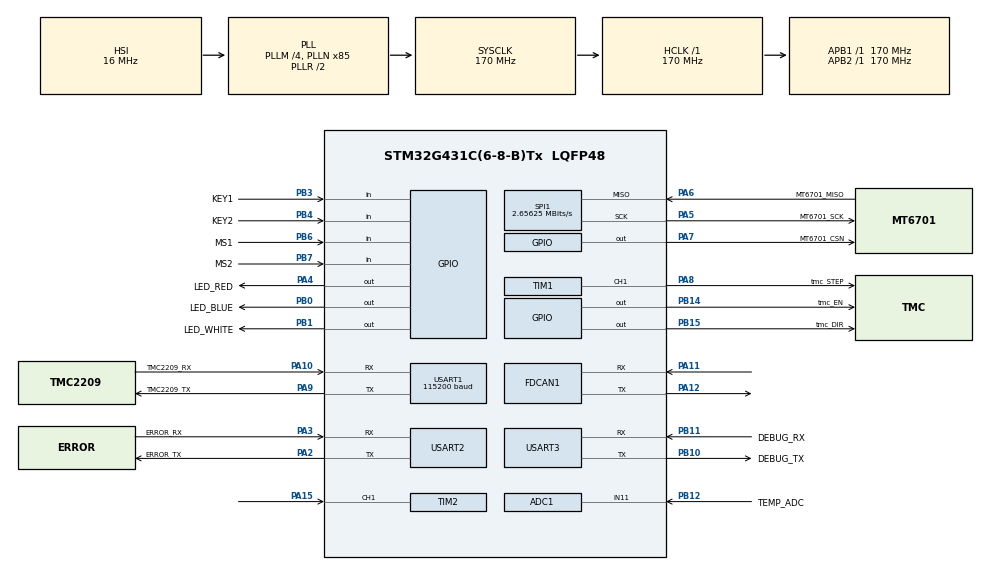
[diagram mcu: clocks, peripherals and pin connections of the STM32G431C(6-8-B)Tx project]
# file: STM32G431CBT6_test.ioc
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ADC1.Channel-1\#ChannelRegularConversion=ADC_CHANNEL_11
ADC1.NbrOfConversionFlag=1
ADC1.OffsetNumber-1\#ChannelRegularConversion=ADC_OFFSET_NONE
ADC1.Rank-1\#ChannelRegularConversion=1
ADC1.SamplingTime-1\#ChannelRegularConversion=ADC_SAMPLETIME_247CYCLES_5
ADC1.master=1
FDCAN1.AutoRetransmission=ENABLE
FDCAN1.CalculateBaudRateNominal=499999
FDCAN1.CalculateTimeBitNominal=2000
FDCAN1.CalculateTimeQuantumNominal=58.82352941176471
FDCAN1.ClockDivider=FDCAN_CLOCK_DIV1
FDCAN1.NominalPrescaler=10
FDCAN1.NominalTimeSeg1=28
FDCAN1.NominalTimeSeg2=5
FDCAN1.StdFiltersNbr=1
Mcu.Family=STM32G4
Mcu.Name=STM32G431C(6-8-B)Tx
Mcu.Package=LQFP48
NVIC.FDCAN1_IT0_IRQn=true\:4\:0\:true\:false\:true\:true\:true\:true
NVIC.PriorityGroup=NVIC_PRIORITYGROUP_4
NVIC.TIM1_UP_TIM16_IRQn=true\:0\:0\:false\:false\:true\:true\:true\:true
NVIC.TIM2_IRQn=true\:2\:0\:true\:false\:true\:true\:true\:true
NVIC.TIM6_DAC_IRQn=true\:1\:0\:true\:false\:true\:true\:true\:true
NVIC.USART2_IRQn=true\:3\:0\:true\:false\:true\:true\:true\:true
NVIC.USART3_IRQn=true\:5\:0\:true\:false\:true\:true\:true\:true
PA10.GPIO_Label=TMC2209_RX
PA10.Mode=Asynchronous
PA10.Signal=USART1_RX
PA11.Mode=FDCAN_Activate
PA11.Signal=FDCAN1_RX
PA12.Mode=FDCAN_Activate
PA12.Signal=FDCAN1_TX
PA13.Mode=Serial_Wire
PA13.Signal=SYS_JTMS-SWDIO
PA14.Mode=Serial_Wire
PA14.Signal=SYS_JTCK-SWCLK
PA15.Signal=S_TIM2_CH1
PA2.GPIO_Label=ERROR_TX
PA2.Mode=Asynchronous
PA2.Signal=USART2_TX
PA3.GPIO_Label=ERROR_RX
PA3.Mode=Asynchronous
PA3.Signal=USART2_RX
PA4.GPIO_Label=LED_RED
PA4.Signal=GPIO_Output
PA5.GPIO_Label=MT6701_SCK
PA5.Mode=RX_Only_Simplex_Unidirect_Master
PA5.Signal=SPI1_SCK
PA6.GPIO_Label=MT6701_MISO
PA6.Mode=RX_Only_Simplex_Unidirect_Master
PA6.Signal=SPI1_MISO
PA7.GPIO_Label=MT6701_CSN
PA7.Signal=GPIO_Output
PA8.GPIO_Label=tmc_STEP
PA8.Signal=S_TIM1_CH1
PA9.GPIO_Label=TMC2209_TX
PA9.Mode=Asynchronous
PA9.Signal=USART1_TX
PB0.GPIO_Label=LED_BLUE
PB0.Signal=GPIO_Output
PB1.GPIO_Label=LED_WHITE
PB1.Signal=GPIO_Output
PB10.GPIO_Label=DEBUG_TX
PB10.Mode=Asynchronous
PB10.Signal=USART3_TX
PB11.GPIO_Label=DEBUG_RX
PB11.Mode=Asynchronous
PB11.Signal=USART3_RX
PB12.GPIO_Label=TEMP_ADC
PB12.Mode=IN11-Single-Ended
PB12.Signal=ADC1_IN11
PB14.GPIO_Label=tmc_EN
PB14.GPIO_PuPd=GPIO_PULLUP
PB14.PinState=GPIO_PIN_SET
PB14.Signal=GPIO_Output
PB15.GPIO_Label=tmc_DIR
PB15.Signal=GPIO_Output
PB3.GPIO_Label=KEY1
PB3.GPIO_PuPd=GPIO_PULLUP
PB3.Signal=GPIO_Input
PB4.GPIO_Label=KEY2
PB4.GPIO_PuPd=GPIO_PULLUP
PB4.Signal=GPIO_Input
PB6.GPIO_Label=MS1
PB6.GPIO_PuPd=GPIO_PULLUP
PB6.Signal=GPIO_Input
PB7.GPIO_Label=MS2
PB7.GPIO_PuPd=GPIO_PULLUP
PB7.Signal=GPIO_Input
PF0-OSC_IN.Mode=HSE-External-Oscillator
PF0-OSC_IN.Signal=RCC_OSC_IN
PF1-OSC_OUT.Mode=HSE-External-Oscillator
PF1-OSC_OUT.Signal=RCC_OSC_OUT
ProjectManager.HeapSize=0x200
ProjectManager.StackSize=0x400
ProjectManager.TargetToolchain=MDK-ARM V5.32
RCC.ADC12Freq_Value=170000000
RCC.AHBFreq_Value=170000000
RCC.APB1Freq_Value=170000000
RCC.APB1TimFreq_Value=170000000
RCC.APB2Freq_Value=170000000
RCC.APB2TimFreq_Value=170000000
RCC.CortexFreq_Value=170000000
RCC.EXTERNAL_CLOCK_VALUE=12288000
RCC.HCLKFreq_Value=170000000
RCC.HSE_VALUE=8000000
RCC.HSI48_VALUE=48000000
RCC.HSI_VALUE=16000000
RCC.LSE_VALUE=32768
RCC.PLLM=RCC_PLLM_DIV4
RCC.PLLN=85
RCC.SYSCLKFreq_VALUE=170000000
RCC.SYSCLKSource=RCC_SYSCLKSOURCE_PLLCLK
RCC.USBFreq_Value=170000000
RCC.VCOOutputFreq_Value=340000000
SH.S_TIM1_CH1.0=TIM1_CH1,PWM Generation1 CH1
SH.S_TIM2_CH1.0=TIM2_CH1,PWM_Input_1
SPI1.BaudRatePrescaler=SPI_BAUDRATEPRESCALER_64
SPI1.CLKPolarity=SPI_POLARITY_HIGH
SPI1.CRCCalculation=SPI_CRCCALCULATION_DISABLE
SPI1.CalculateBaudRate=2.65625 MBits/s
SPI1.DataSize=SPI_DATASIZE_8BIT
SPI1.Direction=SPI_DIRECTION_2LINES_RXONLY
SPI1.Mode=SPI_MODE_MASTER
SPI1.NSSPMode=SPI_NSS_PULSE_DISABLE
SPI1.VirtualType=VM_MASTER
TIM1.AutomaticOutput=TIM_AUTOMATICOUTPUT_ENABLE
TIM1.Channel-PWM\ Generation1\ CH1=TIM_CHANNEL_1
TIM1.PeriodNoDither=1000
TIM1.Prescaler=169
TIM2.ICFilter_1=4
TIM2.ICFilter_2=4
TIM2.PeriodNoDither=4294967295
TIM2.Prescaler=169
TIM6.PeriodNoDither=999
TIM6.Prescaler=169
USART1.BaudRate=115200
USART1.VirtualMode-Asynchronous=VM_ASYNC
USART2.VirtualMode-Asynchronous=VM_ASYNC
USART3.VirtualMode-Asynchronous=VM_ASYNC
VP_SYS_VS_DBSignals.Mode=DisableDeadBatterySignals
VP_TIM1_VS_ClockSourceINT.Mode=Internal
VP_TIM2_VS_ClockSourceINT.Mode=Internal
VP_TIM6_VS_ClockSourceINT.Mode=Enable_Timer
board=custom

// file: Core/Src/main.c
/* USER CODE BEGIN Header */
/**
 ******************************************************************************
 * @file           : main.c
 * @brief          : Main program body
 ******************************************************************************
 * @attention
 *
 * Copyright (c) 2026 STMicroelectronics.
 * All rights reserved.
 *
 * This software is licensed under terms that can be found in the LICENSE file
 * in the root directory of this software component.
 * If no LICENSE file comes with this software, it is provided AS-IS.
 *
 ******************************************************************************
 */
/* USER CODE END Header */
#include "main.h"

/* USER CODE BEGIN Includes */
#include "../../Src/Step42App.h"
/* USER CODE END Includes */

ADC_HandleTypeDef hadc1;

FDCAN_HandleTypeDef hfdcan1;

SPI_HandleTypeDef hspi1;

TIM_HandleTypeDef htim1;
TIM_HandleTypeDef htim2;
TIM_HandleTypeDef htim6;

UART_HandleTypeDef huart1;
UART_HandleTypeDef huart2;
UART_HandleTypeDef huart3;

void SystemClock_Config(void);
static void MX_GPIO_Init(void);
static void MX_FDCAN1_Init(void);
static void MX_SPI1_Init(void);
static void MX_TIM1_Init(void);
static void MX_TIM2_Init(void);
static void MX_USART1_UART_Init(void);
static void MX_USART2_UART_Init(void);
static void MX_TIM6_Init(void);
static void MX_ADC1_Init(void);
static void MX_USART3_UART_Init(void);

int main(void)
{

  /* MCU Configuration--------------------------------------------------------*/

  /* Reset of all peripherals, Initializes the Flash interface and the Systick. */
  HAL_Init();

  /* Configure the system clock */
  SystemClock_Config();

  /* Initialize all configured peripherals */
  MX_GPIO_Init();
  MX_FDCAN1_Init();
  MX_SPI1_Init();
  MX_TIM1_Init();
  MX_TIM2_Init();
  MX_USART1_UART_Init();
  MX_USART2_UART_Init();
  MX_TIM6_Init();
  MX_ADC1_Init();
  MX_USART3_UART_Init();
  /* USER CODE BEGIN 2 */
  Step42App_Init();
  /* USER CODE END 2 */

  /* Infinite loop */
  while (1)
  {

    /* USER CODE BEGIN 3 */
    Step42App_Loop();
  }
  /* USER CODE END 3 */
}

void SystemClock_Config(void)
{
  RCC_OscInitTypeDef RCC_OscInitStruct = {0};
  RCC_ClkInitTypeDef RCC_ClkInitStruct = {0};

  /** Configure the main internal regulator output voltage
  */
  HAL_PWREx_ControlVoltageScaling(PWR_REGULATOR_VOLTAGE_SCALE1_BOOST);

  /** Initializes the RCC Oscillators according to the specified parameters
  * in the RCC_OscInitTypeDef structure.
  */
  RCC_OscInitStruct.OscillatorType = RCC_OSCILLATORTYPE_HSI;
  RCC_OscInitStruct.HSIState = RCC_HSI_ON;
  RCC_OscInitStruct.HSICalibrationValue = RCC_HSICALIBRATION_DEFAULT;
  RCC_OscInitStruct.PLL.PLLState = RCC_PLL_ON;
  RCC_OscInitStruct.PLL.PLLSource = RCC_PLLSOURCE_HSI;
  RCC_OscInitStruct.PLL.PLLM = RCC_PLLM_DIV4;
  RCC_OscInitStruct.PLL.PLLN = 85;
  RCC_OscInitStruct.PLL.PLLP = RCC_PLLP_DIV2;
  RCC_OscInitStruct.PLL.PLLQ = RCC_PLLQ_DIV2;
  RCC_OscInitStruct.PLL.PLLR = RCC_PLLR_DIV2;
  if (HAL_RCC_OscConfig(&RCC_OscInitStruct) != HAL_OK)
  {
    Error_Handler();
  }

  /** Initializes the CPU, AHB and APB buses clocks
  */
  RCC_ClkInitStruct.ClockType = RCC_CLOCKTYPE_HCLK|RCC_CLOCKTYPE_SYSCLK
                              |RCC_CLOCKTYPE_PCLK1|RCC_CLOCKTYPE_PCLK2;
  RCC_ClkInitStruct.SYSCLKSource = RCC_SYSCLKSOURCE_PLLCLK;
  RCC_ClkInitStruct.AHBCLKDivider = RCC_SYSCLK_DIV1;
  RCC_ClkInitStruct.APB1CLKDivider = RCC_HCLK_DIV1;
  RCC_ClkInitStruct.APB2CLKDivider = RCC_HCLK_DIV1;

  if (HAL_RCC_ClockConfig(&RCC_ClkInitStruct, FLASH_LATENCY_4) != HAL_OK)
  {
    Error_Handler();
  }
}

static void MX_ADC1_Init(void)
{

  ADC_MultiModeTypeDef multimode = {0};
  ADC_ChannelConfTypeDef sConfig = {0};

  /** Common config
  */
  hadc1.Instance = ADC1;
  hadc1.Init.ClockPrescaler = ADC_CLOCK_SYNC_PCLK_DIV4;
  hadc1.Init.Resolution = ADC_RESOLUTION_12B;
  hadc1.Init.DataAlign = ADC_DATAALIGN_RIGHT;
  hadc1.Init.GainCompensation = 0;
  hadc1.Init.ScanConvMode = ADC_SCAN_DISABLE;
  hadc1.Init.EOCSelection = ADC_EOC_SINGLE_CONV;
  hadc1.Init.LowPowerAutoWait = DISABLE;
  hadc1.Init.ContinuousConvMode = DISABLE;
  hadc1.Init.NbrOfConversion = 1;
  hadc1.Init.DiscontinuousConvMode = DISABLE;
  hadc1.Init.ExternalTrigConv = ADC_SOFTWARE_START;
  hadc1.Init.ExternalTrigConvEdge = ADC_EXTERNALTRIGCONVEDGE_NONE;
  hadc1.Init.DMAContinuousRequests = DISABLE;
  hadc1.Init.Overrun = ADC_OVR_DATA_PRESERVED;
  hadc1.Init.OversamplingMode = DISABLE;
  if (HAL_ADC_Init(&hadc1) != HAL_OK)
  {
    Error_Handler();
  }

  /** Configure the ADC multi-mode
  */
  multimode.Mode = ADC_MODE_INDEPENDENT;
  if (HAL_ADCEx_MultiModeConfigChannel(&hadc1, &multimode) != HAL_OK)
  {
    Error_Handler();
  }

  /** Configure Regular Channel
  */
  sConfig.Channel = ADC_CHANNEL_11;
  sConfig.Rank = ADC_REGULAR_RANK_1;
  sConfig.SamplingTime = ADC_SAMPLETIME_247CYCLES_5;
  sConfig.SingleDiff = ADC_SINGLE_ENDED;
  sConfig.OffsetNumber = ADC_OFFSET_NONE;
  sConfig.Offset = 0;
  if (HAL_ADC_ConfigChannel(&hadc1, &sConfig) != HAL_OK)
  {
    Error_Handler();
  }

}

static void MX_FDCAN1_Init(void)
{

  hfdcan1.Instance = FDCAN1;
  hfdcan1.Init.ClockDivider = FDCAN_CLOCK_DIV1;
  hfdcan1.Init.FrameFormat = FDCAN_FRAME_CLASSIC;
  hfdcan1.Init.Mode = FDCAN_MODE_NORMAL;
  hfdcan1.Init.AutoRetransmission = ENABLE;
  hfdcan1.Init.TransmitPause = DISABLE;
  hfdcan1.Init.ProtocolException = DISABLE;
  hfdcan1.Init.NominalPrescaler = 10;
  hfdcan1.Init.NominalSyncJumpWidth = 1;
  hfdcan1.Init.NominalTimeSeg1 = 28;
  hfdcan1.Init.NominalTimeSeg2 = 5;
  hfdcan1.Init.DataPrescaler = 1;
  hfdcan1.Init.DataSyncJumpWidth = 1;
  hfdcan1.Init.DataTimeSeg1 = 1;
  hfdcan1.Init.DataTimeSeg2 = 1;
  hfdcan1.Init.StdFiltersNbr = 1;
  hfdcan1.Init.ExtFiltersNbr = 0;
  hfdcan1.Init.TxFifoQueueMode = FDCAN_TX_FIFO_OPERATION;
  if (HAL_FDCAN_Init(&hfdcan1) != HAL_OK)
  {
    Error_Handler();
  }

}

static void MX_SPI1_Init(void)
{

  /* SPI1 parameter configuration*/
  hspi1.Instance = SPI1;
  hspi1.Init.Mode = SPI_MODE_MASTER;
  hspi1.Init.Direction = SPI_DIRECTION_2LINES_RXONLY;
  hspi1.Init.DataSize = SPI_DATASIZE_8BIT;
  hspi1.Init.CLKPolarity = SPI_POLARITY_HIGH;
  hspi1.Init.CLKPhase = SPI_PHASE_1EDGE;
  hspi1.Init.NSS = SPI_NSS_SOFT;
  hspi1.Init.BaudRatePrescaler = SPI_BAUDRATEPRESCALER_64;
  hspi1.Init.FirstBit = SPI_FIRSTBIT_MSB;
  hspi1.Init.TIMode = SPI_TIMODE_DISABLE;
  hspi1.Init.CRCCalculation = SPI_CRCCALCULATION_DISABLE;
  hspi1.Init.CRCPolynomial = 7;
  hspi1.Init.CRCLength = SPI_CRC_LENGTH_DATASIZE;
  hspi1.Init.NSSPMode = SPI_NSS_PULSE_DISABLE;
  if (HAL_SPI_Init(&hspi1) != HAL_OK)
  {
    Error_Handler();
  }

}

static void MX_TIM1_Init(void)
{

  TIM_ClockConfigTypeDef sClockSourceConfig = {0};
  TIM_MasterConfigTypeDef sMasterConfig = {0};
  TIM_OC_InitTypeDef sConfigOC = {0};
  TIM_BreakDeadTimeConfigTypeDef sBreakDeadTimeConfig = {0};

  htim1.Instance = TIM1;
  htim1.Init.Prescaler = 169;
  htim1.Init.CounterMode = TIM_COUNTERMODE_UP;
  htim1.Init.Period = 1000;
  htim1.Init.ClockDivision = TIM_CLOCKDIVISION_DIV1;
  htim1.Init.RepetitionCounter = 0;
  htim1.Init.AutoReloadPreload = TIM_AUTORELOAD_PRELOAD_DISABLE;
  if (HAL_TIM_Base_Init(&htim1) != HAL_OK)
  {
    Error_Handler();
  }
  sClockSourceConfig.ClockSource = TIM_CLOCKSOURCE_INTERNAL;
  if (HAL_TIM_ConfigClockSource(&htim1, &sClockSourceConfig) != HAL_OK)
  {
    Error_Handler();
  }
  if (HAL_TIM_PWM_Init(&htim1) != HAL_OK)
  {
    Error_Handler();
  }
  sMasterConfig.MasterOutputTrigger = TIM_TRGO_RESET;
  sMasterConfig.MasterOutputTrigger2 = TIM_TRGO2_RESET;
  sMasterConfig.MasterSlaveMode = TIM_MASTERSLAVEMODE_DISABLE;
  if (HAL_TIMEx_MasterConfigSynchronization(&htim1, &sMasterConfig) != HAL_OK)
  {
    Error_Handler();
  }
  sConfigOC.OCMode = TIM_OCMODE_PWM1;
  sConfigOC.Pulse = 0;
  sConfigOC.OCPolarity = TIM_OCPOLARITY_HIGH;
  sConfigOC.OCNPolarity = TIM_OCNPOLARITY_HIGH;
  sConfigOC.OCFastMode = TIM_OCFAST_DISABLE;
  sConfigOC.OCIdleState = TIM_OCIDLESTATE_RESET;
  sConfigOC.OCNIdleState = TIM_OCNIDLESTATE_RESET;
  if (HAL_TIM_PWM_ConfigChannel(&htim1, &sConfigOC, TIM_CHANNEL_1) != HAL_OK)
  {
    Error_Handler();
  }
  sBreakDeadTimeConfig.OffStateRunMode = TIM_OSSR_DISABLE;
  sBreakDeadTimeConfig.OffStateIDLEMode = TIM_OSSI_DISABLE;
  sBreakDeadTimeConfig.LockLevel = TIM_LOCKLEVEL_OFF;
  sBreakDeadTimeConfig.DeadTime = 0;
  sBreakDeadTimeConfig.BreakState = TIM_BREAK_DISABLE;
  sBreakDeadTimeConfig.BreakPolarity = TIM_BREAKPOLARITY_HIGH;
  sBreakDeadTimeConfig.BreakFilter = 0;
  sBreakDeadTimeConfig.BreakAFMode = TIM_BREAK_AFMODE_INPUT;
  sBreakDeadTimeConfig.Break2State = TIM_BREAK2_DISABLE;
  sBreakDeadTimeConfig.Break2Polarity = TIM_BREAK2POLARITY_HIGH;
  sBreakDeadTimeConfig.Break2Filter = 0;
  sBreakDeadTimeConfig.Break2AFMode = TIM_BREAK_AFMODE_INPUT;
  sBreakDeadTimeConfig.AutomaticOutput = TIM_AUTOMATICOUTPUT_ENABLE;
  if (HAL_TIMEx_ConfigBreakDeadTime(&htim1, &sBreakDeadTimeConfig) != HAL_OK)
  {
    Error_Handler();
  }
  HAL_TIM_MspPostInit(&htim1);

}

static void MX_TIM2_Init(void)
{

  TIM_ClockConfigTypeDef sClockSourceConfig = {0};
  TIM_SlaveConfigTypeDef sSlaveConfig = {0};
  TIM_IC_InitTypeDef sConfigIC = {0};
  TIM_MasterConfigTypeDef sMasterConfig = {0};

  htim2.Instance = TIM2;
  htim2.Init.Prescaler = 169;
  htim2.Init.CounterMode = TIM_COUNTERMODE_UP;
  htim2.Init.Period = 4294967295;
  htim2.Init.ClockDivision = TIM_CLOCKDIVISION_DIV1;
  htim2.Init.AutoReloadPreload = TIM_AUTORELOAD_PRELOAD_DISABLE;
  if (HAL_TIM_Base_Init(&htim2) != HAL_OK)
  {
    Error_Handler();
  }
  sClockSourceConfig.ClockSource = TIM_CLOCKSOURCE_INTERNAL;
  if (HAL_TIM_ConfigClockSource(&htim2, &sClockSourceConfig) != HAL_OK)
  {
    Error_Handler();
  }
  if (HAL_TIM_IC_Init(&htim2) != HAL_OK)
  {
    Error_Handler();
  }
  sSlaveConfig.SlaveMode = TIM_SLAVEMODE_RESET;
  sSlaveConfig.InputTrigger = TIM_TS_TI1FP1;
  sSlaveConfig.TriggerPolarity = TIM_INPUTCHANNELPOLARITY_RISING;
  sSlaveConfig.TriggerPrescaler = TIM_ICPSC_DIV1;
  sSlaveConfig.TriggerFilter = 4;
  if (HAL_TIM_SlaveConfigSynchro(&htim2, &sSlaveConfig) != HAL_OK)
  {
    Error_Handler();
  }
  sConfigIC.ICPolarity = TIM_INPUTCHANNELPOLARITY_RISING;
  sConfigIC.ICSelection = TIM_ICSELECTION_DIRECTTI;
  sConfigIC.ICPrescaler = TIM_ICPSC_DIV1;
  sConfigIC.ICFilter = 4;
  if (HAL_TIM_IC_ConfigChannel(&htim2, &sConfigIC, TIM_CHANNEL_1) != HAL_OK)
  {
    Error_Handler();
  }
  sConfigIC.ICPolarity = TIM_INPUTCHANNELPOLARITY_FALLING;
  sConfigIC.ICSelection = TIM_ICSELECTION_INDIRECTTI;
  if (HAL_TIM_IC_ConfigChannel(&htim2, &sConfigIC, TIM_CHANNEL_2) != HAL_OK)
  {
    Error_Handler();
  }
  sMasterConfig.MasterOutputTrigger = TIM_TRGO_RESET;
  sMasterConfig.MasterSlaveMode = TIM_MASTERSLAVEMODE_DISABLE;
  if (HAL_TIMEx_MasterConfigSynchronization(&htim2, &sMasterConfig) != HAL_OK)
  {
    Error_Handler();
  }

}

static void MX_TIM6_Init(void)
{

  TIM_MasterConfigTypeDef sMasterConfig = {0};

  htim6.Instance = TIM6;
  htim6.Init.Prescaler = 169;
  htim6.Init.CounterMode = TIM_COUNTERMODE_UP;
  htim6.Init.Period = 999;
  htim6.Init.AutoReloadPreload = TIM_AUTORELOAD_PRELOAD_DISABLE;
  if (HAL_TIM_Base_Init(&htim6) != HAL_OK)
  {
    Error_Handler();
  }
  sMasterConfig.MasterOutputTrigger = TIM_TRGO_RESET;
  sMasterConfig.MasterSlaveMode = TIM_MASTERSLAVEMODE_DISABLE;
  if (HAL_TIMEx_MasterConfigSynchronization(&htim6, &sMasterConfig) != HAL_OK)
  {
    Error_Handler();
  }

}

static void MX_USART1_UART_Init(void)
{

  huart1.Instance = USART1;
  huart1.Init.BaudRate = 115200;
  huart1.Init.WordLength = UART_WORDLENGTH_8B;
  huart1.Init.StopBits = UART_STOPBITS_1;
  huart1.Init.Parity = UART_PARITY_NONE;
  huart1.Init.Mode = UART_MODE_TX_RX;
  huart1.Init.HwFlowCtl = UART_HWCONTROL_NONE;
  huart1.Init.OverSampling = UART_OVERSAMPLING_16;
  huart1.Init.OneBitSampling = UART_ONE_BIT_SAMPLE_DISABLE;
  huart1.Init.ClockPrescaler = UART_PRESCALER_DIV1;
  huart1.AdvancedInit.AdvFeatureInit = UART_ADVFEATURE_NO_INIT;
  if (HAL_UART_Init(&huart1) != HAL_OK)
  {
    Error_Handler();
  }
  if (HAL_UARTEx_SetTxFifoThreshold(&huart1, UART_TXFIFO_THRESHOLD_1_8) != HAL_OK)
  {
    Error_Handler();
  }
  if (HAL_UARTEx_SetRxFifoThreshold(&huart1, UART_RXFIFO_THRESHOLD_1_8) != HAL_OK)
  {
    Error_Handler();
  }
  if (HAL_UARTEx_DisableFifoMode(&huart1) != HAL_OK)
  {
    Error_Handler();
  }

}

static void MX_USART2_UART_Init(void)
{

  huart2.Instance = USART2;
  huart2.Init.BaudRate = 115200;
  huart2.Init.WordLength = UART_WORDLENGTH_8B;
  huart2.Init.StopBits = UART_STOPBITS_1;
  huart2.Init.Parity = UART_PARITY_NONE;
  huart2.Init.Mode = UART_MODE_TX_RX;
  huart2.Init.HwFlowCtl = UART_HWCONTROL_NONE;
  huart2.Init.OverSampling = UART_OVERSAMPLING_16;
  huart2.Init.OneBitSampling = UART_ONE_BIT_SAMPLE_DISABLE;
  huart2.Init.ClockPrescaler = UART_PRESCALER_DIV1;
  huart2.AdvancedInit.AdvFeatureInit = UART_ADVFEATURE_NO_INIT;
  if (HAL_UART_Init(&huart2) != HAL_OK)
  {
    Error_Handler();
  }
  if (HAL_UARTEx_SetTxFifoThreshold(&huart2, UART_TXFIFO_THRESHOLD_1_8) != HAL_OK)
  {
    Error_Handler();
  }
  if (HAL_UARTEx_SetRxFifoThreshold(&huart2, UART_RXFIFO_THRESHOLD_1_8) != HAL_OK)
  {
    Error_Handler();
  }
  if (HAL_UARTEx_DisableFifoMode(&huart2) != HAL_OK)
  {
    Error_Handler();
  }

}

static void MX_USART3_UART_Init(void)
{

  huart3.Instance = USART3;
  huart3.Init.BaudRate = 115200;
  huart3.Init.WordLength = UART_WORDLENGTH_8B;
  huart3.Init.StopBits = UART_STOPBITS_1;
  huart3.Init.Parity = UART_PARITY_NONE;
  huart3.Init.Mode = UART_MODE_TX_RX;
  huart3.Init.HwFlowCtl = UART_HWCONTROL_NONE;
  huart3.Init.OverSampling = UART_OVERSAMPLING_16;
  huart3.Init.OneBitSampling = UART_ONE_BIT_SAMPLE_DISABLE;
  huart3.Init.ClockPrescaler = UART_PRESCALER_DIV1;
  huart3.AdvancedInit.AdvFeatureInit = UART_ADVFEATURE_NO_INIT;
  if (HAL_UART_Init(&huart3) != HAL_OK)
  {
    Error_Handler();
  }
  if (HAL_UARTEx_SetTxFifoThreshold(&huart3, UART_TXFIFO_THRESHOLD_1_8) != HAL_OK)
  {
    Error_Handler();
  }
  if (HAL_UARTEx_SetRxFifoThreshold(&huart3, UART_RXFIFO_THRESHOLD_1_8) != HAL_OK)
  {
    Error_Handler();
  }
  if (HAL_UARTEx_DisableFifoMode(&huart3) != HAL_OK)
  {
    Error_Handler();
  }

}

static void MX_GPIO_Init(void)
{
  GPIO_InitTypeDef GPIO_InitStruct = {0};

  /* GPIO Ports Clock Enable */
  __HAL_RCC_GPIOF_CLK_ENABLE();
  __HAL_RCC_GPIOA_CLK_ENABLE();
  __HAL_RCC_GPIOB_CLK_ENABLE();

  /*Configure GPIO pin Output Level */
  HAL_GPIO_WritePin(GPIOA, LED_RED_Pin|MT6701_CSN_Pin, GPIO_PIN_RESET);

  /*Configure GPIO pin Output Level */
  HAL_GPIO_WritePin(GPIOB, LED_BLUE_Pin|LED_WHITE_Pin|tmc_DIR_Pin, GPIO_PIN_RESET);

  /*Configure GPIO pin Output Level */
  HAL_GPIO_WritePin(tmc_EN_GPIO_Port, tmc_EN_Pin, GPIO_PIN_SET);

  /*Configure GPIO pins : LED_RED_Pin MT6701_CSN_Pin */
  GPIO_InitStruct.Pin = LED_RED_Pin|MT6701_CSN_Pin;
  GPIO_InitStruct.Mode = GPIO_MODE_OUTPUT_PP;
  GPIO_InitStruct.Pull = GPIO_NOPULL;
  GPIO_InitStruct.Speed = GPIO_SPEED_FREQ_LOW;
  HAL_GPIO_Init(GPIOA, &GPIO_InitStruct);

  /*Configure GPIO pins : LED_BLUE_Pin LED_WHITE_Pin tmc_DIR_Pin */
  GPIO_InitStruct.Pin = LED_BLUE_Pin|LED_WHITE_Pin|tmc_DIR_Pin;
  GPIO_InitStruct.Mode = GPIO_MODE_OUTPUT_PP;
  GPIO_InitStruct.Pull = GPIO_NOPULL;
  GPIO_InitStruct.Speed = GPIO_SPEED_FREQ_LOW;
  HAL_GPIO_Init(GPIOB, &GPIO_InitStruct);

  /*Configure GPIO pin : tmc_EN_Pin */
  GPIO_InitStruct.Pin = tmc_EN_Pin;
  GPIO_InitStruct.Mode = GPIO_MODE_OUTPUT_PP;
  GPIO_InitStruct.Pull = GPIO_PULLUP;
  GPIO_InitStruct.Speed = GPIO_SPEED_FREQ_LOW;
  HAL_GPIO_Init(tmc_EN_GPIO_Port, &GPIO_InitStruct);

  /*Configure GPIO pins : KEY1_Pin KEY2_Pin MS1_Pin MS2_Pin */
  GPIO_InitStruct.Pin = KEY1_Pin|KEY2_Pin|MS1_Pin|MS2_Pin;
  GPIO_InitStruct.Mode = GPIO_MODE_INPUT;
  GPIO_InitStruct.Pull = GPIO_PULLUP;
  HAL_GPIO_Init(GPIOB, &GPIO_InitStruct);

}

/* USER CODE BEGIN 4 */
void HAL_TIM_PeriodElapsedCallback(TIM_HandleTypeDef *htim)
{
  Step42App_TIMPeriodElapsedCallback(htim);
}

void HAL_UART_ErrorCallback(UART_HandleTypeDef *huart)
{
  Step42App_UARTErrorCallback(huart);
}

void HAL_UART_RxCpltCallback(UART_HandleTypeDef *huart)
{
  Step42App_UARTRxCompleteCallback(huart);
}

void HAL_TIM_IC_CaptureCallback(TIM_HandleTypeDef *htim)
{
  Step42App_TIMCaptureCallback(htim);
}

/* USER CODE END 4 */

void Error_Handler(void)
{
  __disable_irq();
  while (1)
  {
  }
}
